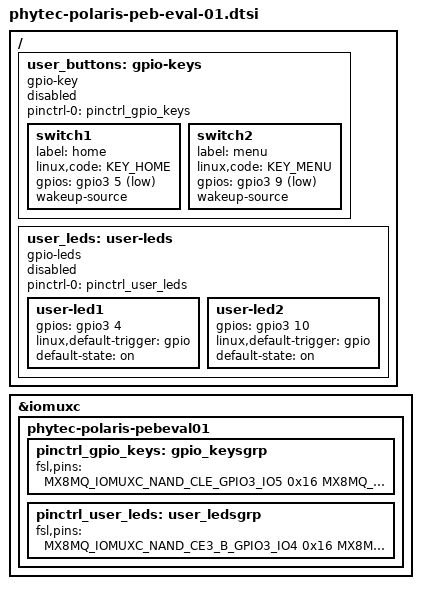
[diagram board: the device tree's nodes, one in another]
/*
 * Copyright (C) 2018 PHYTEC Messtechnik GmbH
 * Author: Norbert Wesp <n.wesp@phytec.de>
 *
 * This program is free software; you can redistribute it and/or
 * modify it under the terms of the GNU General Public License
 * as published by the Free Software Foundation; either version 2
 * of the License, or (at your option) any later version.
 *
 * This program is distributed in the hope that it will be useful,
 * but WITHOUT ANY WARRANTY; without even the implied warranty of
 * MERCHANTABILITY or FITNESS FOR A PARTICULAR PURPOSE.  See the
 * GNU General Public License for more details.
 */

/ {
	user_buttons: gpio-keys {
		compatible = "gpio-key";
		pinctrl-names = "default";
		pinctrl-0 = <&pinctrl_gpio_keys>;
		status = "disabled";

		switch1 {
			label = "home";
			linux,code = <KEY_HOME>;
			gpios = <&gpio3 5 GPIO_ACTIVE_LOW>;
			wakeup-source;
		};

		switch2 {
			label = "menu";
			linux,code = <KEY_MENU>;
			gpios = <&gpio3 9 GPIO_ACTIVE_LOW>;
			wakeup-source;
		};
	};

	user_leds: user-leds {
		compatible = "gpio-leds";
		pinctrl-names = "default";
		pinctrl-0 = <&pinctrl_user_leds>;
		status = "disabeld";

		user-led1 {
			gpios = <&gpio3 4 GPIO_ACTIVE_HIGH>;
			linux,default-trigger = "gpio";
			default-state = "on";
		};

		user-led2 {
			gpios = <&gpio3 10 GPIO_ACTIVE_HIGH>;
			linux,default-trigger = "gpio";
			default-state = "on";
		};
	};
};

&iomuxc {
	phytec-polaris-pebeval01 {
		pinctrl_gpio_keys: gpio_keysgrp {
			fsl,pins = <
				MX8MQ_IOMUXC_NAND_CLE_GPIO3_IO5		0x16
				MX8MQ_IOMUXC_NAND_DATA03_GPIO3_IO9	0x16
			>;
		};

		pinctrl_user_leds: user_ledsgrp {
			fsl,pins = <
				MX8MQ_IOMUXC_NAND_CE3_B_GPIO3_IO4	0x16
				MX8MQ_IOMUXC_NAND_DATA04_GPIO3_IO10	0x16
			>;
		};
	};
};
